# STM32F413 register map
File version: 1.9
CPU: CM4 r0p1, little endian, MPU, FPU, 4 interrupt priority bits
Registers are 32-bit, read-write, reset 0x0 unless marked. A register's access mark holds for its fields unless they carry their own. Offsets are from the block's base; [hi:lo] are bit positions; {n}, {i} and the like mark numbered series; 'fields as' and 'values as' point back to an identical list.

## RCC — Reset and clock control
Base 0x40023800
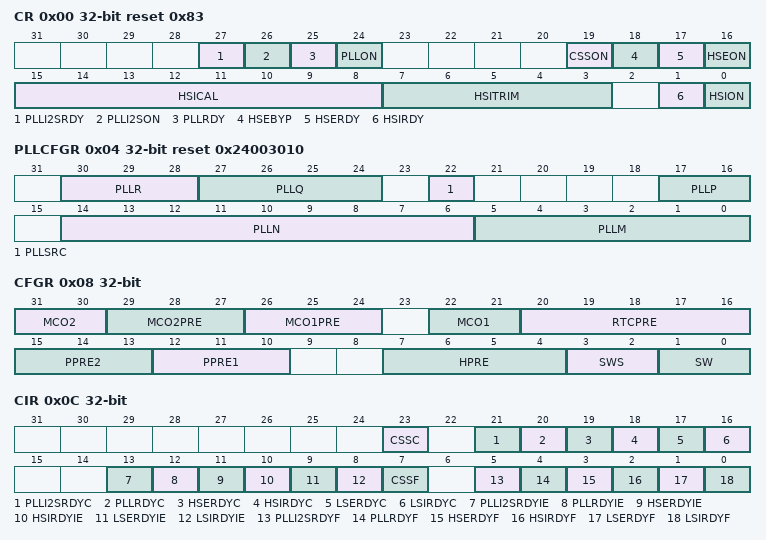
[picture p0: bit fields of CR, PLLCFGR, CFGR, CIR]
0x00 CR reset 0x83 — clock control register
  [27] PLLI2SRDY — PLLI2S clock ready flag
    on read: 0=NotReady (Clock not ready); 1=Ready (Clock ready)
  [26] PLLI2SON — PLLI2S enable
    0=Off (Clock Off); 1=On (Clock On)
  [25] PLLRDY — Main PLL (PLL) clock ready flag
    on read: 0=NotReady (Clock not ready); 1=Ready (Clock ready)
  [24] PLLON — Main PLL (PLL) enable
    0=Off (Clock Off); 1=On (Clock On)
  [19] CSSON — Clock security system enable
    0=Off (Clock security system disabled (clock detector OFF)); 1=On (Clock security system enable (clock detector ON if the HSE is ready, OFF if not))
  [18] HSEBYP — HSE clock bypass
    0=NotBypassed (HSE crystal oscillator not bypassed); 1=Bypassed (HSE crystal oscillator bypassed with external clock)
  [17] HSERDY — HSE clock ready flag
    on read: 0=NotReady (Clock not ready); 1=Ready (Clock ready)
  [16] HSEON — HSE clock enable
    0=Off (Clock Off); 1=On (Clock On)
  [15:8] HSICAL — Internal high-speed clock calibration
  [7:3] HSITRIM — Internal high-speed clock trimming
  [1] HSIRDY — Internal high-speed clock ready flag
    on read: 0=NotReady (Clock not ready); 1=Ready (Clock ready)
  [0] HSION — Internal high-speed clock enable
    0=Off (Clock Off); 1=On (Clock On)
0x04 PLLCFGR reset 0x24003010 — PLL configuration register
  [30:28] PLLR range 2..7 — Main PLL (PLL) division factor for I2S, DFSDM clocks
  [27:24] PLLQ range 2..15 — Main PLL (PLL) division factor for USB OTG FS, SDIO and random number generator clocks
  [22] PLLSRC — Main PLL(PLL) and audio PLL (PLLI2S) entry clock source
    0=HSI (HSI clock selected as PLL and PLLI2S clock entry); 1=HSE (HSE oscillator clock selected as PLL and PLLI2S clock entry)
  [17:16] PLLP — Main PLL (PLL) division factor for main system clock
    0=Div2 (PLLP=2); 1=Div4 (PLLP=4); 2=Div6 (PLLP=6); 3=Div8 (PLLP=8)
  [14:6] PLLN range 50..432 — Main PLL (PLL) multiplication factor for VCO
  [5:0] PLLM range 2..63 — Division factor for the main PLL (PLL) and audio PLL (PLLI2S) input clock
0x08 CFGR access not given — clock configuration register
  [31:30] MCO2 rw — Microcontroller clock output 2
    0=SYSCLK (System clock (SYSCLK) selected); 1=PLLI2S (PLLI2S clock selected); 2=HSE (HSE oscillator clock selected); 3=PLL (PLL clock selected)
  [29:27] MCO2PRE rw — MCO2 prescaler
    {v}=Div{v-2} (Division by {v-2}) (v=4..7); other=Div1 (No division)
  [26:24] MCO1PRE rw — MCO1 prescaler
    values as MCO2PRE
  [22:21] MCO1 rw — Microcontroller clock output 1
    0=HSI (HSI clock selected); 1=LSE (LSE oscillator selected); 2=HSE (HSE oscillator clock selected); 3=PLL (PLL clock selected)
  [20:16] RTCPRE rw — HSE division factor for RTC clock
  [15:13] PPRE2 rw — APB high-speed prescaler (APB2)
    4=Div2 (HCLK divided by 2); 5=Div4 (HCLK divided by 4); 6=Div8 (HCLK divided by 8); 7=Div16 (HCLK divided by 16); other=Div1 (HCLK not divided)
  [12:10] PPRE1 rw — APB Low speed prescaler (APB1)
    values as PPRE2
  [7:4] HPRE rw — AHB prescaler
    8=Div2 (SYSCLK divided by 2); 9=Div4 (SYSCLK divided by 4); 10=Div8 (SYSCLK divided by 8); 11=Div16 (SYSCLK divided by 16); 12=Div64 (SYSCLK divided by 64); 13=Div128 (SYSCLK divided by 128); 14=Div256 (SYSCLK divided by 256); 15=Div512 (SYSCLK divided by 512); other=Div1 (SYSCLK not divided)
  [3:2] SWS — System clock switch status
    on read: 0=HSI (HSI oscillator used as system clock); 1=HSE (HSE oscillator used as system clock); 2=PLL (PLL used as system clock)
  [1:0] SW — System clock switch
    0=HSI (HSI selected as system clock); 1=HSE (HSE selected as system clock); 2=PLL (PLL selected as system clock)
0x0C CIR access per field — clock interrupt register
  [23] CSSC wo — Clock security system interrupt clear
    1=Clear CSSF flag
  [21] PLLI2SRDYC wo — PLLI2S ready interrupt clear
    1=Clear interrupt flag
  [20] PLLRDYC wo — Main PLL(PLL) ready interrupt clear
    1=Clear interrupt flag
  [19] HSERDYC wo — HSE ready interrupt clear
    1=Clear interrupt flag
  [18] HSIRDYC wo — HSI ready interrupt clear
    1=Clear interrupt flag
  [17] LSERDYC wo — LSE ready interrupt clear
    1=Clear interrupt flag
  [16] LSIRDYC wo — LSI ready interrupt clear
    1=Clear interrupt flag
  [13] PLLI2SRDYIE rw — PLLI2S ready interrupt enable
    0=Disabled (Interrupt disabled); 1=Enabled (Interrupt enabled)
  [12] PLLRDYIE rw — Main PLL (PLL) ready interrupt enable
    values as PLLI2SRDYIE
  [11] HSERDYIE rw — HSE ready interrupt enable
    values as PLLI2SRDYIE
  [10] HSIRDYIE rw — HSI ready interrupt enable
    values as PLLI2SRDYIE
  [9] LSERDYIE rw — LSE ready interrupt enable
    values as PLLI2SRDYIE
  [8] LSIRDYIE rw — LSI ready interrupt enable
    values as PLLI2SRDYIE
  [7] CSSF ro — Clock security system interrupt flag
    0=NotInterrupted (No clock security interrupt caused by HSE clock failure); 1=Interrupted (Clock security interrupt caused by HSE clock failure)
  [5] PLLI2SRDYF ro — PLLI2S ready interrupt flag
    0=NotInterrupted (No clock ready interrupt); 1=Interrupted (Clock ready interrupt)
  [4] PLLRDYF ro — Main PLL (PLL) ready interrupt flag
    values as PLLI2SRDYF
  [3] HSERDYF ro — HSE ready interrupt flag
    values as PLLI2SRDYF
  [2] HSIRDYF ro — HSI ready interrupt flag
    values as PLLI2SRDYF
  [1] LSERDYF ro — LSE ready interrupt flag
    values as PLLI2SRDYF
  [0] LSIRDYF ro — LSI ready interrupt flag
    values as PLLI2SRDYF
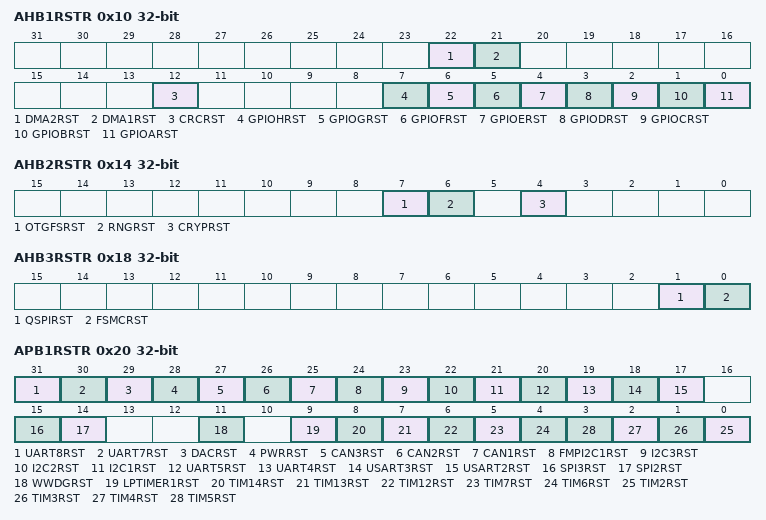
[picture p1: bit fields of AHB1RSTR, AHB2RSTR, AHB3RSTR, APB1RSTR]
0x10 AHB1RSTR — AHB1 peripheral reset register
  [all] fields
    1=Reset the selected module
  [22] DMA2RST — DMA2 reset
  [21] DMA1RST — DMA2 reset
  [12] CRCRST — CRC reset
  [7] GPIOHRST — IO port H reset
  [6] GPIOGRST — IO port G reset
  [5] GPIOFRST — IO port F reset
  [4] GPIOERST — IO port E reset
  [3] GPIODRST — IO port D reset
  [2] GPIOCRST — IO port C reset
  [1] GPIOBRST — IO port B reset
  [0] GPIOARST — IO port A reset
0x14 AHB2RSTR — AHB2 peripheral reset register
  [all] fields
    1=Reset the selected module
  [7] OTGFSRST — USB OTG FS module reset
  [6] RNGRST
  [4] CRYPRST — CRYP module reset
0x18 AHB3RSTR — peripheral reset register
  [1] QSPIRST — QUADSPI module reset
    1=Reset the selected module
  [0] FSMCRST — Flexible memory controller module reset
    1=Reset the selected module
0x20 APB1RSTR — APB1 peripheral reset register
  [all] fields
    1=Reset the selected module
  [31] UART8RST — UART 8 reset
  [30] UART7RST — UART 7 reset
  [29] DACRST — DAC reset
  [28] PWRRST — Power interface reset
  [27] CAN3RST — CAN 3 reset
  [26] CAN2RST
  [25] CAN1RST
  [24] FMPI2C1RST — FMPI2C1 reset
  [23] I2C3RST — I2C3 reset
  [22] I2C2RST — I2C 2 reset
  [21] I2C1RST — I2C 1 reset
  [20] UART5RST — UART5 reset
  [19] UART4RST — UART4 reset
  [18] USART3RST
  [17] USART2RST — USART 2 reset
  [15] SPI3RST — SPI 3 reset
  [14] SPI2RST — SPI 2 reset
  [11] WWDGRST — Window watchdog reset
  [9] LPTIMER1RST — LPTimer1 reset
  [8] TIM14RST
  [7] TIM13RST
  [6] TIM12RST
  [5] TIM7RST
  [4] TIM6RST
  [n-2] TIM{n}RST (n=2..5) — TIM{n} reset
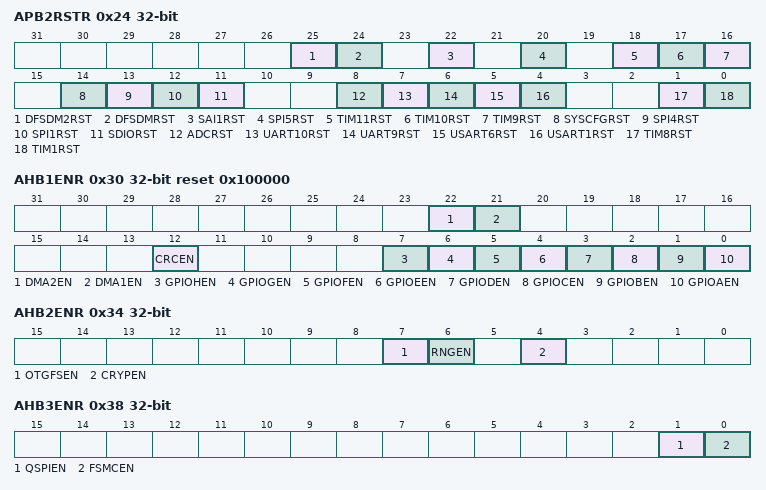
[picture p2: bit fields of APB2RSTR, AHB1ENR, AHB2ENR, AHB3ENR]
0x24 APB2RSTR — APB2 peripheral reset register
  [all] fields
    1=Reset the selected module
  [25] DFSDM2RST — DFSDM2 reset
  [24] DFSDMRST
  [22] SAI1RST — SAI1 reset
  [20] SPI5RST
  [18] TIM11RST — TIM11 reset
  [17] TIM10RST — TIM10 reset
  [16] TIM9RST — TIM9 reset
  [14] SYSCFGRST — System configuration controller reset
  [13] SPI4RST — SPI4 reset
  [12] SPI1RST — SPI 1 reset
  [11] SDIORST — SDIO reset
  [8] ADCRST — ADC interface reset (common to all ADCs)
  [7] UART10RST — UART10 reset
  [6] UART9RST — UART9 reset
  [5] USART6RST — USART6 reset
  [4] USART1RST — USART1 reset
  [1] TIM8RST
  [0] TIM1RST — TIM1 reset
0x30 AHB1ENR reset 0x100000 — AHB1 peripheral clock register
  [all] fields
    0=Disabled (The selected clock is disabled); 1=Enabled (The selected clock is enabled)
  [22] DMA2EN — DMA2 clock enable
  [21] DMA1EN — DMA1 clock enable
  [12] CRCEN — CRC clock enable
  [7] GPIOHEN — IO port H clock enable
  [6] GPIOGEN — IO port G clock enable
  [5] GPIOFEN — IO port F clock enable
  [4] GPIOEEN — IO port E clock enable
  [3] GPIODEN — IO port D clock enable
  [2] GPIOCEN — IO port C clock enable
  [1] GPIOBEN — IO port B clock enable
  [0] GPIOAEN — IO port A clock enable
0x34 AHB2ENR — AHB2 peripheral clock enable register
  [all] fields
    values as the fields of AHB1ENR
  [7] OTGFSEN — USB OTG FS clock enable
  [6] RNGEN
  [4] CRYPEN — CRYP clock enable
0x38 AHB3ENR — AHB3 peripheral clock enable register
  [1] QSPIEN — QUADSPI memory controller module clock enable
    values as the fields of AHB1ENR
  [0] FSMCEN — Flexible memory controller module clock enable
    values as the fields of AHB1ENR
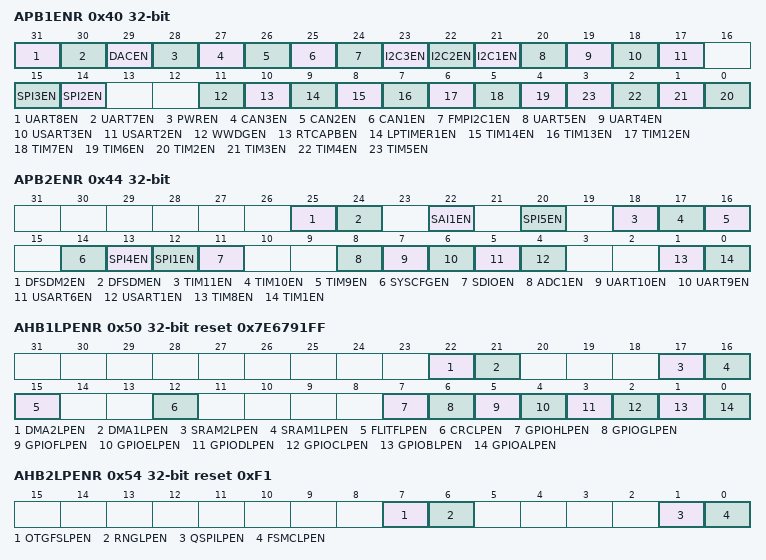
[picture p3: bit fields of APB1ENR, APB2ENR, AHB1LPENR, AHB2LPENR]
0x40 APB1ENR — APB1 peripheral clock enable register
  [all] fields
    values as the fields of AHB1ENR
  [31] UART8EN — UART8 clock enable
  [30] UART7EN — UART7 clock enable
  [29] DACEN — DAC clock enable
  [28] PWREN — Power interface clock enable
  [27] CAN3EN — CAN 3 clock enable
  [26] CAN2EN
  [25] CAN1EN
  [24] FMPI2C1EN — FMPI2C1 clock enable
  [23] I2C3EN — I2C3 clock enable
  [22] I2C2EN — I2C2 clock enable
  [21] I2C1EN — I2C1 clock enable
  [20] UART5EN — UART 5 clock enable
  [19] UART4EN — UART 4 clock enable
  [18] USART3EN
  [17] USART2EN — USART 2 clock enable
  [15] SPI3EN — SPI3 clock enable
  [14] SPI2EN — SPI2 clock enable
  [11] WWDGEN — Window watchdog clock enable
  [10] RTCAPBEN — clock enable
  [9] LPTIMER1EN — LPTimer 1 clock enable
  [8] TIM14EN
  [7] TIM13EN
  [6] TIM12EN
  [5] TIM7EN
  [4] TIM6EN
  [n-2] TIM{n}EN (n=2..5) — TIM{n} clock enable
0x44 APB2ENR — APB2 peripheral clock enable register
  [all] fields
    values as the fields of AHB1ENR
  [25] DFSDM2EN — DFSDM2 clock enable
  [24] DFSDMEN
  [22] SAI1EN — SAI 1 clock enable
  [20] SPI5EN — SPI5 clock enable
  [18] TIM11EN — TIM11 clock enable
  [17] TIM10EN — TIM10 clock enable
  [16] TIM9EN — TIM9 clock enable
  [14] SYSCFGEN — System configuration controller clock enable
  [13] SPI4EN — SPI4 clock enable
  [12] SPI1EN — SPI1 clock enable
  [11] SDIOEN — SDIO clock enable
  [8] ADC1EN — ADC1 clock enable
  [7] UART10EN — UART10 clock enable
  [6] UART9EN — UART9 clock enable
  [5] USART6EN — USART6 clock enable
  [4] USART1EN — USART1 clock enable
  [1] TIM8EN
  [0] TIM1EN — TIM1 clock enable
0x50 AHB1LPENR reset 0x7E6791FF — AHB1 peripheral clock enable in low power mode register
  [all] fields
    0=DisabledInSleep (Selected module is disabled during Sleep mode); 1=EnabledInSleep (Selected module is enabled during Sleep mode)
  [22] DMA2LPEN — DMA2 clock enable during Sleep mode
  [21] DMA1LPEN — DMA1 clock enable during Sleep mode
  [17] SRAM2LPEN — SRAM2interface clock enable during Sleep mode
  [16] SRAM1LPEN — SRAM 1interface clock enable during Sleep mode
  [15] FLITFLPEN — Flash interface clock enable during Sleep mode
  [12] CRCLPEN — CRC clock enable during Sleep mode
  [7] GPIOHLPEN — IO port H clock enable during Sleep mode
  [6] GPIOGLPEN — IO port G clock enable during sleep mode
  [5] GPIOFLPEN — IO port F clock enable during sleep mode
  [4] GPIOELPEN — IO port E clock enable during Sleep mode
  [3] GPIODLPEN — IO port D clock enable during Sleep mode
  [2] GPIOCLPEN — IO port C clock enable during Sleep mode
  [1] GPIOBLPEN — IO port B clock enable during Sleep mode
  [0] GPIOALPEN — IO port A clock enable during sleep mode
0x54 AHB2LPENR reset 0xF1 — AHB2 peripheral clock enable in low power mode register
  [all] fields
    values as the fields of AHB1LPENR
  [7] OTGFSLPEN — USB OTG FS clock enable during Sleep mode
  [6] RNGLPEN
  [1] QSPILPEN — QUADSPI memory controller module clock enable during Sleep mode
  [0] FSMCLPEN — Flexible memory controller module clock enable during Sleep mode
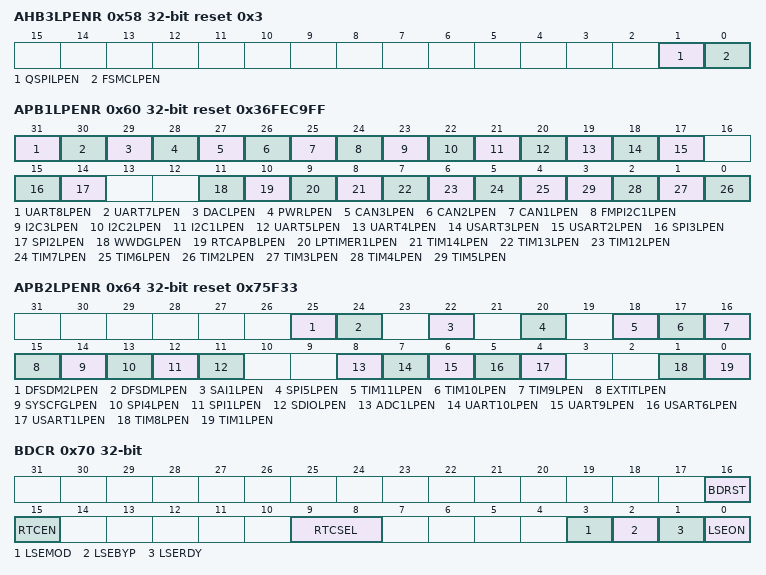
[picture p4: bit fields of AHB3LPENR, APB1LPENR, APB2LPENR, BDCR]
0x58 AHB3LPENR reset 0x3 — AHB3 peripheral clock enable in low power mode register
  [1] QSPILPEN — QUADSPI memory controller module clock enable during Sleep mode
    values as the fields of AHB1LPENR
  [0] FSMCLPEN — Flexible memory controller module clock enable during Sleep mode
    values as the fields of AHB1LPENR
0x60 APB1LPENR reset 0x36FEC9FF — APB1 peripheral clock enable in low power mode register
  [all] fields
    values as the fields of AHB1LPENR
  [31] UART8LPEN — UART8 clock enable during Sleep mode
  [30] UART7LPEN — UART7 clock enable during Sleep mode
  [29] DACLPEN — DAC clock enable during Sleep mode
  [28] PWRLPEN — Power interface clock enable during Sleep mode
  [27] CAN3LPEN — CAN3 clock enable during Sleep mode
  [26] CAN2LPEN
  [25] CAN1LPEN
  [24] FMPI2C1LPEN — FMPI2C1 clock enable during Sleep
  [23] I2C3LPEN — I2C3 clock enable during Sleep mode
  [22] I2C2LPEN — I2C2 clock enable during Sleep mode
  [21] I2C1LPEN — I2C1 clock enable during Sleep mode
  [20] UART5LPEN — UART5 clock enable during Sleep mode
  [19] UART4LPEN — UART4 clock enable during Sleep mode
  [18] USART3LPEN
  [17] USART2LPEN — USART2 clock enable during Sleep mode
  [15] SPI3LPEN — SPI3 clock enable during Sleep mode
  [14] SPI2LPEN — SPI2 clock enable during Sleep mode
  [11] WWDGLPEN — Window watchdog clock enable during Sleep mode
  [10] RTCAPBLPEN — RTC APB clock enable during Sleep mode
  [9] LPTIMER1LPEN — TIM14 clock enable during Sleep mode
  [8] TIM14LPEN
  [7] TIM13LPEN
  [6] TIM12LPEN
  [5] TIM7LPEN
  [4] TIM6LPEN
  [n-2] TIM{n}LPEN (n=2..5) — TIM{n} clock enable during Sleep mode
0x64 APB2LPENR reset 0x75F33 — APB2 peripheral clock enabled in low power mode register
  [all] fields
    values as the fields of AHB1LPENR
  [25] DFSDM2LPEN — DFSDM2 clock enable during Sleep mode
  [24] DFSDMLPEN
  [22] SAI1LPEN — SAI1 clock enable during Sleep mode
  [20] SPI5LPEN — SPI5 clock enable during Sleep mode
  [18] TIM11LPEN — TIM11 clock enable during Sleep mode
  [17] TIM10LPEN — TIM10 clock enable during Sleep mode
  [16] TIM9LPEN — TIM9 clock enable during sleep mode
  [15] EXTITLPEN — EXTIT APB and SYSCTRL PFREE clock enable during Sleep mode
  [14] SYSCFGLPEN — System configuration controller clock enable during Sleep mode
  [13] SPI4LPEN — SPI4 clock enable during Sleep mode
  [12] SPI1LPEN — SPI 1 clock enable during Sleep mode
  [11] SDIOLPEN — SDIO clock enable during Sleep mode
  [8] ADC1LPEN — ADC1 clock enable during Sleep mode
  [7] UART10LPEN — UART10 clock enable during Sleep mode
  [6] UART9LPEN — UART9 clock enable during Sleep mode
  [5] USART6LPEN — USART6 clock enable during Sleep mode
  [4] USART1LPEN — USART1 clock enable during Sleep mode
  [1] TIM8LPEN
  [0] TIM1LPEN — TIM1 clock enable during Sleep mode
0x70 BDCR access not given — Backup domain control register
  [16] BDRST rw — Backup domain software reset
    0=Disabled (Reset not activated); 1=Enabled (Reset the entire RTC domain)
  [15] RTCEN rw — RTC clock enable
    0=Disabled (RTC clock disabled); 1=Enabled (RTC clock enabled)
  [9:8] RTCSEL — RTC clock source selection
    0=NoClock; 1=LSE (LSE oscillator clock used as RTC clock); 2=LSI (LSI oscillator clock used as RTC clock); 3=HSE (HSE oscillator clock divided by a prescaler used as RTC clock)
  [3] LSEMOD rw — External low-speed oscillator bypass
    0=Low (LSE oscillator low power mode selection); 1=High (LSE oscillator high drive mode selection)
  [2] LSEBYP rw — External low-speed oscillator bypass
    0=NotBypassed (LSE crystal oscillator not bypassed); 1=Bypassed (LSE crystal oscillator bypassed with external clock)
  [1] LSERDY ro — External low-speed oscillator ready
    0=NotReady (LSE oscillator not ready); 1=Ready (LSE oscillator ready)
  [0] LSEON rw — External low-speed oscillator enable
    0=Off (LSE oscillator Off); 1=On (LSE oscillator On)
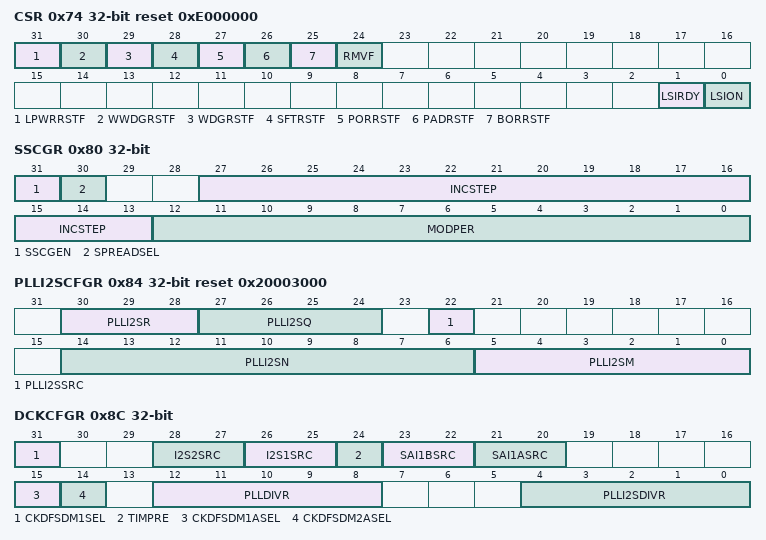
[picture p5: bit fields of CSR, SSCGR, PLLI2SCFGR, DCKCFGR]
0x74 CSR access per field reset 0xE000000 — clock control & status register
  [31] LPWRRSTF rw — Low-power reset flag
    on read: 0=No reset has occured; 1=Reset (A reset has occured)
  [30] WWDGRSTF rw — Window watchdog reset flag
    values as LPWRRSTF
  [29] WDGRSTF rw — Independent watchdog reset flag
    values as LPWRRSTF
  [28] SFTRSTF rw — Software reset flag
    values as LPWRRSTF
  [27] PORRSTF rw — POR/PDR reset flag
    values as LPWRRSTF
  [26] PADRSTF rw — PIN reset flag
    values as LPWRRSTF
  [25] BORRSTF rw — BOR reset flag
    values as LPWRRSTF
  [24] RMVF rw — Remove reset flag
    on write: 1=Clears the reset flag
  [1] LSIRDY ro — Internal low-speed oscillator ready
    0=NotReady (LSI oscillator not ready); 1=Ready (LSI oscillator ready)
  [0] LSION rw — Internal low-speed oscillator enable
    0=Off (LSI oscillator Off); 1=On (LSI oscillator On)
0x80 SSCGR — spread spectrum clock generation register
  [31] SSCGEN — Spread spectrum modulation enable
    0=Disabled (Spread spectrum modulation disabled); 1=Enabled (Spread spectrum modulation enabled)
  [30] SPREADSEL — Spread Select
    0=Center spread; 1=Down spread
  [27:13] INCSTEP — Incrementation step
  [12:0] MODPER — Modulation period
0x84 PLLI2SCFGR reset 0x20003000 — PLLI2S configuration register
  [30:28] PLLI2SR range 2..7 — PLLI2S division factor for I2S clocks
  [27:24] PLLI2SQ range 2..15 — PLLI2S division factor for USB OTG FS/SDIO/RNG clock
  [22] PLLI2SSRC — PLLI2S entry clock source
    0=HSE_HSI (HSE or HSI depending on PLLSRC of PLLCFGR); 1=External AFI clock (CK_PLLI2S_EXT) selected as PLL clock entry
  [14:6] PLLI2SN range 50..432 — PLLI2S multiplication factor for VCO
  [5:0] PLLI2SM range 2..63 — Division factor for the main PLL (PLL) and audio PLL (PLLI2S) input clock
0x8C DCKCFGR — Dedicated Clocks Configuration Register
  [31] CKDFSDM1SEL — DFSDM1 Kernel clock selection
    0=APB2 (APB2 clock used as Kernel clock); 1=SYSCLK (System clock used as Kernel clock)
  [28:27] I2S2SRC — I2S APB2 clocks source selection (I2S1/4/5)
    0=PLLI2SR (I2Sx clock frequency = f(PLLI2S_R)); 1=I2S_CKIN (I2Sx clock frequency = I2S_CKIN Alternate function input frequency); 2=PLLR (I2Sx clock frequency = f(PLL_R)); 3=HSI_HSE (I2Sx clock frequency = HSI/HSE depends on PLLSRC bit (PLLCFGR[22]))
  [26:25] I2S1SRC — I2S APB1 clocks source selection (I2S2/3)
    values as I2S2SRC
  [24] TIMPRE — Timers clocks prescalers selection
    0=Mul1Or2 (If the APB prescaler is configured 1, TIMxCLK = PCLKx. Otherwise, TIMxCLK = 2xPCLKx); 1=Mul1Or4 (If the APB prescaler is configured 1, 2 or 4, TIMxCLK = HCLK. Otherwise, TIMxCLK = 4xPCLKx)
  [23:22] SAI1BSRC — SAI1-B clock source selection
    0=PLLSAI (SAI1-B clock frequency = f(PLLSAI_Q) / PLLSAIDIVQ); 1=PLLI2S (SAI1-B clock frequency = f(PLLI2S_Q) / PLLI2SDIVQ); 2=I2S_CKIN (SAI1-B clock frequency = Alternate function input frequency)
  [21:20] SAI1ASRC — SAI1-A clock source selection
    0=PLLSAI (SAI1-A clock frequency = f(PLLSAI_Q) / PLLSAIDIVQ); 1=PLLI2S (SAI1-A clock frequency = f(PLLI2S_Q) / PLLI2SDIVQ); 2=I2S_CKIN (SAI1-A clock frequency = Alternate function input frequency)
  [15] CKDFSDM1ASEL — DFSDM1 audio clock selection.
    0=I2S1 (CK_I2S_APB1 selected as audio clock); 1=I2S2 (CK_I2S_APB2 selected as audio clock)
  [14] CKDFSDM2ASEL — DFSDM2 audio clock selection
    values as CKDFSDM1ASEL
  [12:8] PLLDIVR — PLL division factor for SAI1 A/B clock
    {v}=Div{v+1} (PLLSAIDIVQ = /{v+1}) (v=0..31)
  [4:0] PLLI2SDIVR — PLLI2S division factor for SAI1 A/B clock
    {v}=Div{v+1} (PLLI2SDIVQ = /{v+1}) (v=0..31)
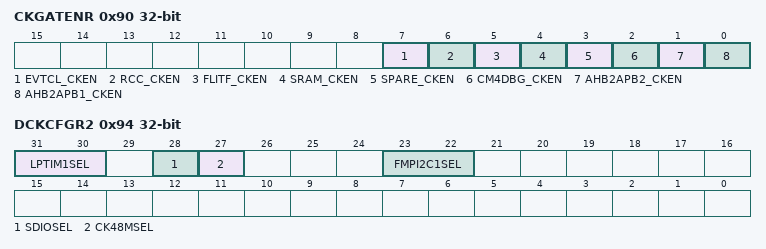
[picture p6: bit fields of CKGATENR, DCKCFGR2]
0x90 CKGATENR — RCC clocks gated enable register
  [all] fields
    0=Enabled (The clock gating is enabled); 1=Disabled (The clock gating is disabled, the clock is always enabled)
  [7] EVTCL_CKEN
  [6] RCC_CKEN — RCC clock enable
  [5] FLITF_CKEN — Flash Interface clock enable
  [4] SRAM_CKEN — SRQAM controller clock enable
  [3] SPARE_CKEN — Spare clock enable
  [2] CM4DBG_CKEN — Cortex M4 ETM clock enable
  [1] AHB2APB2_CKEN — AHB to APB2 Bridge clock enable
  [0] AHB2APB1_CKEN — AHB to APB1 Bridge clock enable
0x94 DCKCFGR2 — Dedicated Clocks Configuration Register
  [31:30] LPTIM1SEL — LPTIM1 kernel clock source selection
    0=APB1 (APB1 clock (PCLK1) selected as LPTILM1 clock); 1=LSI (LSI clock is selected as LPTILM1 clock); 2=HSI (HSI clock is selected as LPTILM1 clock); 3=LSE (LSE clock is selected as LPTILM1 clock)
  [28] SDIOSEL — SDIO clock selection.
    0=CK48M (48 MHz clock is selected as SD clock); 1=SYSCLK (System clock is selected as SD clock)
  [27] CK48MSEL — SDIO/USBFS clock selection.
    0=PLL (48MHz clock from PLL is selected); 1=PLLSAI (48MHz clock from PLLSAI is selected)
  [23:22] FMPI2C1SEL — I2CFMP1 kernel clock source selection
    0=APB (APB clock selected as I2C clock); 1=SYSCLK (System clock selected as I2C clock); 2=HSI (HSI clock selected as I2C clock)
